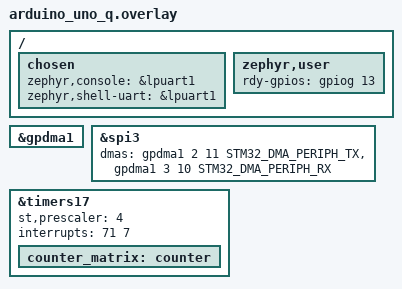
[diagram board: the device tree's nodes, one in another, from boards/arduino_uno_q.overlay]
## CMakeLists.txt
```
# SPDX-License-Identifier: GPL-2.0-or-later
# Copyright (C) 2026 andrewsharmon
cmake_minimum_required(VERSION 3.20.0)
find_package(Zephyr REQUIRED HINTS $ENV{ZEPHYR_BASE})
project(qstep_spi_echo)

target_sources(app PRIVATE src/main.c src/matrix.c)
```

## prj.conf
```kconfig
# SPDX-License-Identifier: GPL-2.0-or-later
# Copyright (C) 2026 andrewsharmon
CONFIG_GPIO=y
CONFIG_SPI=y
CONFIG_SPI_SLAVE=y
CONFIG_SPI_STM32_DMA=y
CONFIG_DMA=y
CONFIG_COUNTER=y
CONFIG_PRINTK=y
CONFIG_CONSOLE=y
CONFIG_UART_CONSOLE=y
CONFIG_ASSERT=n
```

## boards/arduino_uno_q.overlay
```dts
/*
 * SPDX-License-Identifier: GPL-2.0-or-later
 * Copyright (C) 2026 andrewsharmon
 */
/*
 * QStep SPI link test for the UNO Q STM32U585.
 * SPI3 (internal link to the QRB2210 spi5 / spidev0.0) runs as a DMA slave.
 * GPDMA1 request lines on the U5: SPI3_RX = 10, SPI3_TX = 11.
 */
#include <zephyr/dt-bindings/dma/stm32_dma.h>

/ {
	chosen {
		/* LPUART1 is wired to the Linux side (/dev/ttyHS1), so our log is
		 * readable from the MPU once arduino-router is stopped. */
		zephyr,console = &lpuart1;
		zephyr,shell-uart = &lpuart1;
	};

	zephyr,user {
		rdy-gpios = <&gpiog 13 GPIO_ACTIVE_HIGH>; /* "Internal SPI RDY" */
	};
};

&gpdma1 {
	status = "okay";
};

&spi3 {
	status = "okay";
	dmas = <&gpdma1 2 11 STM32_DMA_PERIPH_TX>,
	       <&gpdma1 3 10 STM32_DMA_PERIPH_RX>;
	dma-names = "tx", "rx";
};

/* TIM17 scans the charlieplexed LED matrix at the lowest IRQ priority so it
 * can never delay the SPI link (or, later, step generation). */
&timers17 {
	status = "okay";
	st,prescaler = <4>;
	interrupts = <71 7>;

	counter_matrix: counter {
		status = "okay";
	};
};
```

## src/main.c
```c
/*
 * SPDX-License-Identifier: GPL-2.0-or-later
 * Copyright (C) 2026 andrewsharmon
 */
/*
 * QStep SPI link test firmware (STM32U585 side).
 *
 * Linux (spidev0.0, master) clocks fixed-size frames into SPI3 (slave, DMA).
 * Each reply carries the previous request back so the master can check every
 * byte of the round trip:
 *
 *   request  : [0]=0xA5 [1]=seq [2..3]=unused [4..N-1]=payload
 *   reply    : [0]=0x5A [1]=seq of previous request [2..3]=frames rx (LE16)
 *              [4..N-1]=payload of previous request
 *
 * RDY (PG13) is high while the slave is armed and waiting for a frame.
 * Stats are printed once per second on LPUART1 (/dev/ttyHS1 on Linux).
 * The LED matrix shows "Linux" scrolling over "CNC" while this runs.
 */

#include <zephyr/kernel.h>
#include <zephyr/device.h>
#include <zephyr/drivers/gpio.h>
#include <zephyr/drivers/spi.h>
#include <zephyr/sys/printk.h>
#include <string.h>

#include "matrix.h"

#define FRAME_LEN 64

static const struct device *const spi = DEVICE_DT_GET(DT_NODELABEL(spi3));
static const struct gpio_dt_spec rdy = GPIO_DT_SPEC_GET(DT_PATH(zephyr_user), rdy_gpios);

static const struct spi_config spi_cfg = {
	.operation = SPI_OP_MODE_SLAVE | SPI_WORD_SET(8) | SPI_TRANSFER_MSB,
	/* The master drives SCLK, but the driver still validates this value
	 * against the prescaler table, so it must not be 0. */
	.frequency = 80000000,
	.slave = 0,
};

static uint8_t rx_buf[FRAME_LEN] __aligned(32);
static uint8_t tx_buf[FRAME_LEN] __aligned(32);

static volatile uint32_t frames, bad_len, bad_hdr, errors;
static volatile int last_err;

/* printk on the polled UART busy-waits ~5 ms per line, so report from the
 * lowest-priority thread; the SPI loop in main() preempts it. */
static void report_thread(void *a, void *b, void *c)
{
	for (;;) {
		k_msleep(1000);
		printk("frames=%u bad_len=%u bad_hdr=%u err=%u (last %d)\n", frames, bad_len,
		       bad_hdr, errors, last_err);
	}
}

K_THREAD_DEFINE(report, 1024, report_thread, NULL, NULL, NULL,
		K_LOWEST_APPLICATION_THREAD_PRIO, 0, 0);

int main(void)
{
	printk("\nqstep spi-echo: frame %d bytes\n", FRAME_LEN);

	if (matrix_start() != 0) {
		printk("matrix: failed to start\n");
	}
	if (!device_is_ready(spi) || !gpio_is_ready_dt(&rdy)) {
		printk("spi3/rdy not ready\n");
		return 0;
	}
	gpio_pin_configure_dt(&rdy, GPIO_OUTPUT_INACTIVE);

	memset(tx_buf, 0, sizeof(tx_buf));
	tx_buf[0] = 0x5A;

	struct spi_buf txb = {.buf = tx_buf, .len = FRAME_LEN};
	struct spi_buf rxb = {.buf = rx_buf, .len = FRAME_LEN};
	struct spi_buf_set txs = {.buffers = &txb, .count = 1};
	struct spi_buf_set rxs = {.buffers = &rxb, .count = 1};

	for (;;) {
		gpio_pin_set_dt(&rdy, 1);
		int ret = spi_transceive(spi, &spi_cfg, &txs, &rxs);

		gpio_pin_set_dt(&rdy, 0);

		if (ret < 0) {
			errors++;
			last_err = ret;
		} else if (ret != FRAME_LEN) {
			bad_len++;
		} else if (rx_buf[0] != 0xA5) {
			bad_hdr++;
		} else {
			frames++;
			/* Echo this request back in the next transfer. */
			tx_buf[0] = 0x5A;
			tx_buf[1] = rx_buf[1];
			tx_buf[2] = frames & 0xFF;
			tx_buf[3] = (frames >> 8) & 0xFF;
			memcpy(&tx_buf[4], &rx_buf[4], FRAME_LEN - 4);
		}
	}
	return 0;
}
```

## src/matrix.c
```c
/*
 * SPDX-License-Identifier: Apache-2.0
 * Copyright (C) 2026 andrewsharmon
 * Copyright (c) Arduino s.r.l. and/or its affiliated companies (LED matrix pin map, from ArduinoCore-zephyr loader/matrix.inc)
 */
/*
 * UNO Q 13x8 LED matrix: "Linux" scrolling over a fixed "CNC".
 *
 * The 104 LEDs are charlieplexed on PF0..PF10 and only one LED is lit at a
 * time. TIM17 steps through them from a lowest-priority interrupt; the scroll
 * position is advanced by a normal Zephyr thread.
 * Pin pairs match Arduino's loader (ArduinoCore-zephyr/loader/matrix.inc).
 */

#include <zephyr/kernel.h>
#include <zephyr/device.h>
#include <zephyr/drivers/counter.h>
#include <stm32u5xx.h>
#include <string.h>

#include "matrix.h"

#define COLS     13
#define ROWS     8
#define NUM_LEDS (COLS * ROWS)

static const uint8_t pins[NUM_LEDS][2] = {
	{0, 1}, {1, 0}, {0, 2}, {2, 0}, {1, 2}, {2, 1}, {0, 3}, {3, 0}, {1, 3}, {3, 1},
	{2, 3}, {3, 2}, {0, 4}, {4, 0}, {1, 4}, {4, 1}, {2, 4}, {4, 2}, {3, 4}, {4, 3},
	{0, 5}, {5, 0}, {1, 5}, {5, 1}, {2, 5}, {5, 2}, {3, 5}, {5, 3}, {4, 5}, {5, 4},
	{0, 6}, {6, 0}, {1, 6}, {6, 1}, {2, 6}, {6, 2}, {3, 6}, {6, 3}, {4, 6}, {6, 4},
	{5, 6}, {6, 5}, {0, 7}, {7, 0}, {1, 7}, {7, 1}, {2, 7}, {7, 2}, {3, 7}, {7, 3},
	{4, 7}, {7, 4}, {5, 7}, {7, 5}, {6, 7}, {7, 6}, {0, 8}, {8, 0}, {1, 8}, {8, 1},
	{2, 8}, {8, 2}, {3, 8}, {8, 3}, {4, 8}, {8, 4}, {5, 8}, {8, 5}, {6, 8}, {8, 6},
	{7, 8}, {8, 7}, {0, 9}, {9, 0}, {1, 9}, {9, 1}, {2, 9}, {9, 2}, {3, 9}, {9, 3},
	{4, 9}, {9, 4}, {5, 9}, {9, 5}, {6, 9}, {9, 6}, {7, 9}, {9, 7}, {8, 9}, {9, 8},
	{0, 10}, {10, 0}, {1, 10}, {10, 1}, {2, 10}, {10, 2}, {3, 10}, {10, 3}, {4, 10}, {10, 4},
	{5, 10}, {10, 5}, {6, 10}, {10, 6},
};

/* One bit per LED, index = row * COLS + col. */
static volatile uint8_t framebuffer[(NUM_LEDS + 7) / 8];

static void led_set(int idx, bool on)
{
	/* All matrix pins (PF0..PF10) to input = off; leave PF11..PF15 alone. */
	GPIOF->MODER &= 0xFFC00000U;
	if (on) {
		uint8_t hi = pins[idx][0];
		uint8_t lo = pins[idx][1];

		GPIOF->BSRR = (1U << hi) | (1U << (lo + 16));
		GPIOF->MODER |= (1U << (hi * 2)) | (1U << (lo * 2));
	}
}

static void scan_isr(const struct device *dev, void *user_data)
{
	static int i;

	led_set(i, (framebuffer[i >> 3] >> (i & 7)) & 1);
	i = (i + 1) % NUM_LEDS;
}

/*
 * Two-line display: "Linux" scrolls on the top line (rows 0-3), "CNC" stays
 * fixed on the bottom line (rows 5-7). Glyphs are column bitmaps, bit 0 = the
 * top row of their line.
 */

/* Top line, 4 rows: L and i are full height, n/u/x use rows 1-3. */
static const uint8_t linux_cols[] = {
	0x0F, 0x08,       /* L */
	0x00,
	0x0D,             /* i */
	0x00,
	0x0E, 0x02, 0x0C, /* n */
	0x00,
	0x06, 0x08, 0x0E, /* u */
	0x00,
	0x0A, 0x04, 0x0A, /* x */
	0x00, 0x00, 0x00, 0x00, /* gap before it wraps around */
};

/* Bottom line, 3 rows: C (3 wide), N (4 wide), C. */
static const uint8_t cnc_cols[] = {
	0x07, 0x05, 0x05,       /* C */
	0x00,
	0x07, 0x01, 0x02, 0x07, /* N */
	0x00,
	0x07, 0x05, 0x05,       /* C */
};

#define TOP_ROW    0
#define TOP_ROWS   4
#define BOTTOM_ROW 5
#define BOTTOM_ROWS 3

static void put_col(uint8_t *fb, int col, int row0, int nrows, uint8_t bits)
{
	for (int r = 0; r < nrows; r++) {
		if (bits & (1U << r)) {
			int idx = (row0 + r) * COLS + col;

			fb[idx >> 3] |= 1U << (idx & 7);
		}
	}
}

static void show_frame(int offset)
{
	uint8_t fb[sizeof(framebuffer)] = {0};
	const int n = ARRAY_SIZE(linux_cols);
	const int cnc_x = (COLS - (int)ARRAY_SIZE(cnc_cols)) / 2;

	for (int col = 0; col < COLS; col++) {
		put_col(fb, col, TOP_ROW, TOP_ROWS, linux_cols[(offset + col) % n]);
	}
	for (int i = 0; i < (int)ARRAY_SIZE(cnc_cols); i++) {
		put_col(fb, cnc_x + i, BOTTOM_ROW, BOTTOM_ROWS, cnc_cols[i]);
	}
	memcpy((void *)framebuffer, fb, sizeof(fb));
}

static void scroll_thread(void *a, void *b, void *c)
{
	for (int off = 0;; off = (off + 1) % ARRAY_SIZE(linux_cols)) {
		show_frame(off);
		k_msleep(120);
	}
}

K_THREAD_STACK_DEFINE(scroll_stack, 768);
static struct k_thread scroll_data;

int matrix_start(void)
{
	const struct device *tim = DEVICE_DT_GET(DT_NODELABEL(counter_matrix));
	struct counter_top_cfg top = {
		.callback = scan_isr,
		.flags = 0,
	};

	/* Getting the port device ready makes Zephyr enable the GPIOF clock. */
	if (!device_is_ready(tim) || !device_is_ready(DEVICE_DT_GET(DT_NODELABEL(gpiof)))) {
		return -ENODEV;
	}
	/* 100 us per LED -> ~96 Hz full refresh. */
	top.ticks = counter_us_to_ticks(tim, 100);
	counter_start(tim);
	int err = counter_set_top_value(tim, &top);

	if (err) {
		return err;
	}

	k_thread_create(&scroll_data, scroll_stack, K_THREAD_STACK_SIZEOF(scroll_stack),
			scroll_thread, NULL, NULL, NULL, K_LOWEST_APPLICATION_THREAD_PRIO, 0,
			K_NO_WAIT);
	k_thread_name_set(&scroll_data, "matrix");
	return 0;
}
```

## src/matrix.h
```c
/*
 * SPDX-License-Identifier: GPL-2.0-or-later
 * Copyright (C) 2026 andrewsharmon
 */
#pragma once

/* Start scanning the LED matrix and showing "Linux" (scrolling) over "CNC". */
int matrix_start(void);
```
